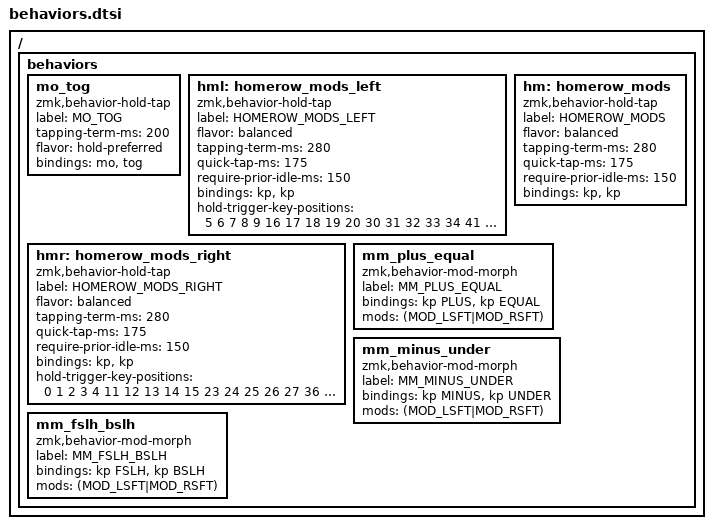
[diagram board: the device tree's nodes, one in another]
/ {
    behaviors {

        mo_tog: mo_tog {
            compatible = "zmk,behavior-hold-tap";
            label = "MO_TOG";
            #binding-cells = <2>;
            tapping-term-ms = <200>;
            flavor = "hold-preferred";
            bindings = <&mo>, <&tog>;
        };

        // ─────────────────────────────────────────────────────────────────────
        //  Timeless homerow mods (introduced 2026-05-24)
        //
        //  Two positional variants — `hml` (left A/S/D/F) and `hmr` (right
        //  J/K/L/;) — share identical timing but each restricts hold-triggering
        //  to keys on the OPPOSITE hand via `hold-trigger-key-positions`. Same-
        //  hand rolls (e.g. "as", "df", "jk", "kl") therefore can NEVER fire a
        //  mod, no matter how slowly you type. The four ingredients that make
        //  these "timeless" — usable at any typing speed, no muscle-memory
        //  retraining around tap-term thresholds:
        //
        //    1.  flavor = "balanced"          decide on key-up order (not the
        //                                     clock); intuitive for rolls
        //    2.  tapping-term-ms = 280        upper bound; rarely the deciding
        //                                     factor because of (3) and (4)
        //    3.  quick-tap-ms = 175           tap+tap within 175 ms always
        //                                     repeats the tap (e.g. fast "ll")
        //    4.  require-prior-idle-ms = 150  if ANY key was pressed in the
        //                                     last 150 ms, this key auto-taps
        //                                     — kills rolling misfires
        //    5.  hold-trigger-key-positions   positional gate: hold only fires
        //                                     when the NEXT key is opposite-hand
        //
        //  Backward-compat alias `hm` is kept (defaults to no positional gate)
        //  so any legacy reference still compiles. New code should pick `hml`
        //  or `hmr` based on which hand the HRM key sits under.
        //
        //  KLOR binding-index map (44 slots, mirrors the matrix transform in
        //  klor.dtsi). LEFT half is highlighted; RIGHT half is the trigger set
        //  for `hml`, and vice-versa:
        //
        //       0  1  2  3  4              5  6  7  8  9          (top)
        //   10 11 12 13 14 15            16 17 18 19 20 21       (home)
        //   22 23 24 25 26 27 28      29 30 31 32 33 34 35       (bottom + encs)
        //                 36 37 38         41 42 43              (thumbs)
        //
        //  Indices 10, 21, 22, 35 are edge `&trans` keys; 28/29 are the
        //  encoder-press positions; 39/40 are unused inner thumbs. None of
        //  those should gate an HRM trigger, so they're omitted from both lists.
        // ─────────────────────────────────────────────────────────────────────

        hml: homerow_mods_left {
            compatible = "zmk,behavior-hold-tap";
            label = "HOMEROW_MODS_LEFT";
            #binding-cells = <2>;
            flavor = "balanced";
            tapping-term-ms = <280>;
            quick-tap-ms = <175>;
            require-prior-idle-ms = <150>;
            bindings = <&kp>, <&kp>;
            // Trigger only when the next key is on the RIGHT half.
            hold-trigger-key-positions = <
                 5  6  7  8  9
                16 17 18 19 20
                30 31 32 33 34
                41 42 43
            >;
        };

        hmr: homerow_mods_right {
            compatible = "zmk,behavior-hold-tap";
            label = "HOMEROW_MODS_RIGHT";
            #binding-cells = <2>;
            flavor = "balanced";
            tapping-term-ms = <280>;
            quick-tap-ms = <175>;
            require-prior-idle-ms = <150>;
            bindings = <&kp>, <&kp>;
            // Trigger only when the next key is on the LEFT half.
            hold-trigger-key-positions = <
                 0  1  2  3  4
                11 12 13 14 15
                23 24 25 26 27
                36 37 38
            >;
        };

        // Legacy non-positional alias. Kept so older config snippets keep
        // compiling, but prefer `hml`/`hmr` for new bindings.
        hm: homerow_mods {
            compatible = "zmk,behavior-hold-tap";
            label = "HOMEROW_MODS";
            #binding-cells = <2>;
            flavor = "balanced";
            tapping-term-ms = <280>;
            quick-tap-ms = <175>;
            require-prior-idle-ms = <150>;
            bindings = <&kp>, <&kp>;
        };

        mm_plus_equal: mm_plus_equal {
            compatible = "zmk,behavior-mod-morph";
            label = "MM_PLUS_EQUAL";
            #binding-cells = <0>;
            bindings = <&kp PLUS>, <&kp EQUAL>;
            mods = <(MOD_LSFT|MOD_RSFT)>;
        };

        mm_minus_under: mm_minus_under {
            compatible = "zmk,behavior-mod-morph";
            label = "MM_MINUS_UNDER";
            #binding-cells = <0>;
            bindings = <&kp MINUS>, <&kp UNDER>;
            mods = <(MOD_LSFT|MOD_RSFT)>;
        };

        mm_fslh_bslh: mm_fslh_bslh {
            compatible = "zmk,behavior-mod-morph";
            label = "MM_FSLH_BSLH";
            #binding-cells = <0>;
            bindings = <&kp FSLH>, <&kp BSLH>;
            mods = <(MOD_LSFT|MOD_RSFT)>;
        };

    };
};
